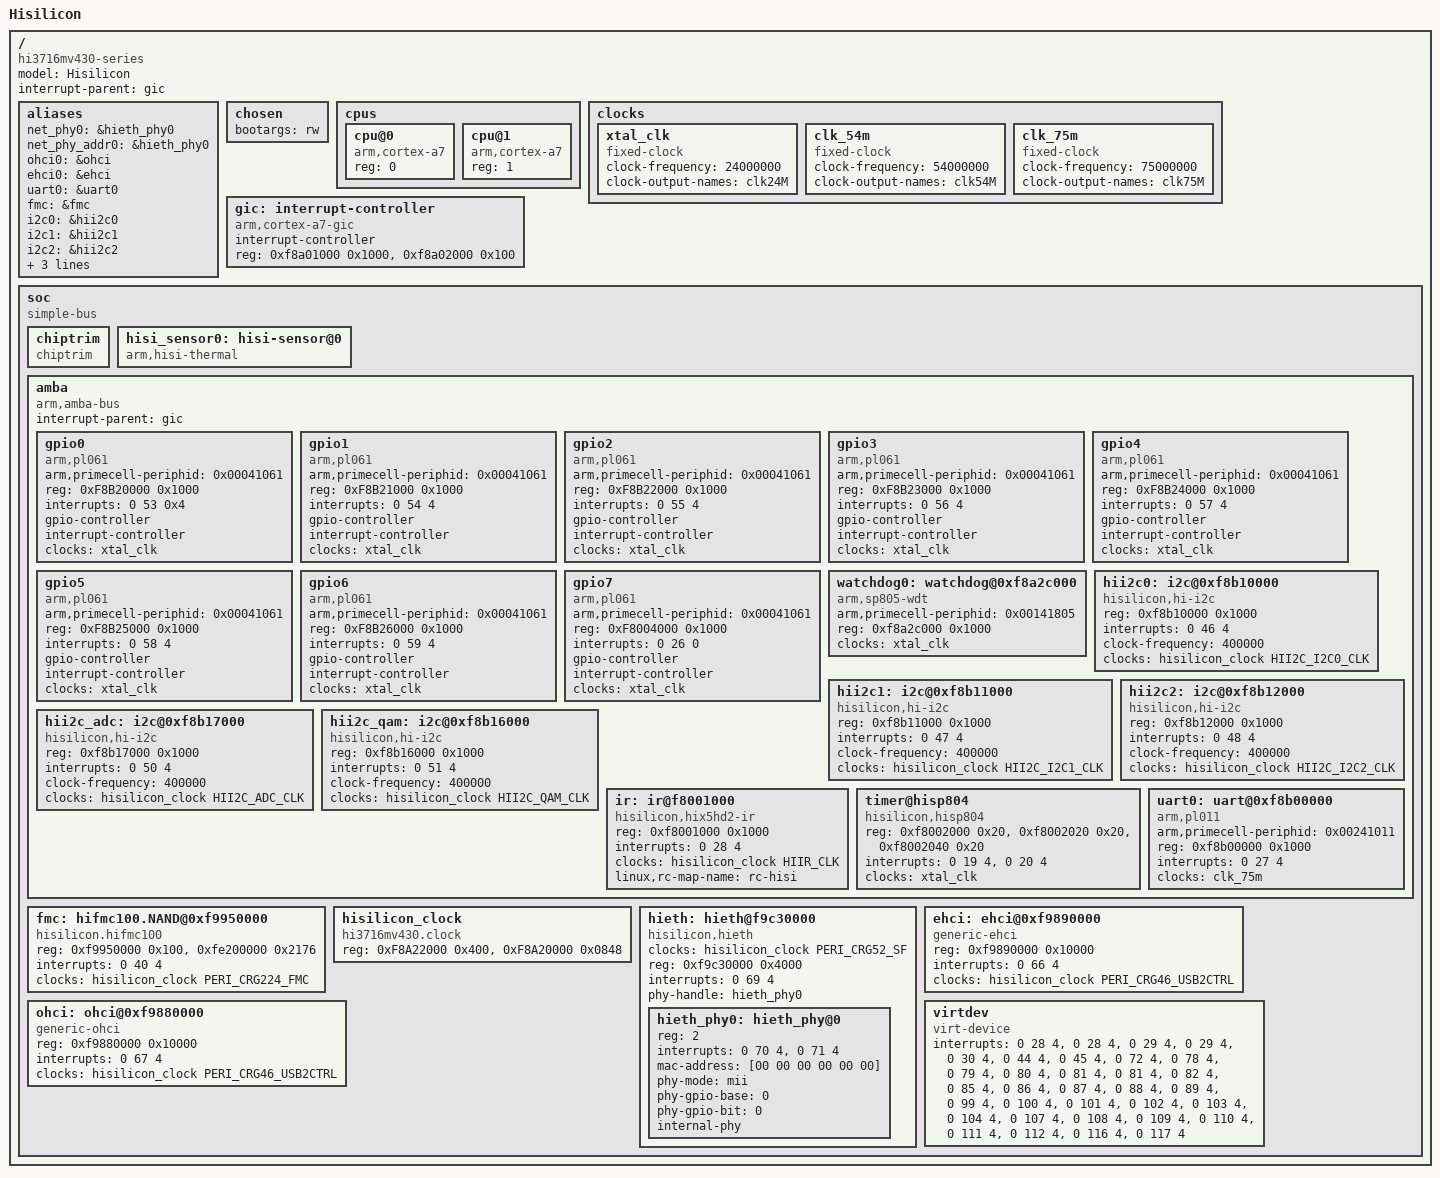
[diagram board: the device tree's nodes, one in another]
/dts-v1/;

#include <dt-bindings/clock/hi3716mv430-clock.h>

/ {
	model = "Hisilicon";
	compatible = "hi3716mv430-series";
	#address-cells = <1>;
	#size-cells = <1>;
	interrupt-parent = <&gic>;

	aliases {
		net_phy0 = &hieth_phy0;
		net_phy_addr0 = &hieth_phy0;
		ohci0= &ohci;
		ehci0= &ehci;
		uart0= &uart0;
		fmc  = &fmc;
		i2c0=&hii2c0;
		i2c1=&hii2c1;
		i2c2=&hii2c2;
		i2c3=&hii2c_qam;
		i2c4=&hii2c_adc;
		chiptrim=&chiptrim;
	};

	chosen {
		bootargs = "rw";
	};

	cpus {
		#address-cells = <1>;
		#size-cells = <0>;

		cpu@0 {
			device_type = "cpu";
			compatible = "arm,cortex-a7";
			reg = <0>;
		};

		cpu@1 {
			device_type = "cpu";
			compatible = "arm,cortex-a7";
			reg = <1>;
		};
	};

	clocks {
		xtal_clk: xtal_clk {
			compatible = "fixed-clock";
			#clock-cells = <0>;
			clock-frequency = <24000000>;
			clock-output-names = "clk24M";
		};

		clk_54m: clk_54m{
			compatible = "fixed-clock";
			#clock-cells = <0>;
			clock-frequency = <54000000>;
			clock-output-names = "clk54M";
		};

		clk_75m: clk_75m{
			compatible = "fixed-clock";
			#clock-cells = <0>;
			clock-frequency = <75000000>;
			clock-output-names = "clk75M";
		};
	};

	gic: interrupt-controller {
		compatible = "arm,cortex-a7-gic";
		#interrupt-cells = <3>;
		#address-cells = <0>;
		interrupt-controller;
		reg = <0xf8a01000 0x1000>,
		      <0xf8a02000 0x100>;
	};
	soc {
		#address-cells = <1>;
		#size-cells = <1>;
		compatible = "simple-bus";
		device_type = "soc";
		ranges = <0x0 0x0 0xffffffff>;

		chiptrim: chiptrim {
			compatible = "chiptrim";
		};

		hisi_sensor0: hisi-sensor@0 {
			compatible = "arm,hisi-thermal";
			#thermal-sensor-cells = <1>;
		};

		amba {
			compatible = "arm,amba-bus";
			#address-cells = <1>;
			#size-cells = <1>;
			interrupt-parent = <&gic>;
			ranges;

			gpio0: gpio0 {
				compatible = "arm,pl061", "arm,primecell";
				arm,primecell-periphid = <0x00041061>;
				reg = <0xF8B20000 0x1000>;
				interrupts = <0 53 0x4>;
				gpio-controller;
				#gpio-cells = <2>;
				interrupt-controller;
				#interrupt-cells = <2>;
				clocks = <&xtal_clk>;
				clock-names = "apb_pclk";
			};

			gpio1: gpio1 {
				compatible = "arm,pl061", "arm,primecell";
				arm,primecell-periphid = <0x00041061>;
				reg = <0xF8B21000 0x1000>;
				interrupts = <0 54 4>;
				gpio-controller;
				#gpio-cells = <2>;
				interrupt-controller;
				#interrupt-cells = <2>;
				clocks = <&xtal_clk>;
				clock-names = "apb_pclk";
			};

			gpio2: gpio2 {
				compatible = "arm,pl061", "arm,primecell";
				arm,primecell-periphid = <0x00041061>;
				reg = <0xF8B22000 0x1000>;
				interrupts = <0 55 4>;
				gpio-controller;
				#gpio-cells = <2>;
				interrupt-controller;
				#interrupt-cells = <2>;
				clocks = <&xtal_clk>;
				clock-names = "apb_pclk";
			};

			gpio3: gpio3 {
				compatible = "arm,pl061", "arm,primecell";
				arm,primecell-periphid = <0x00041061>;
				reg = <0xF8B23000 0x1000>;
				interrupts = <0 56 4>;
				gpio-controller;
				#gpio-cells = <2>;
				interrupt-controller;
				#interrupt-cells = <2>;
				clocks = <&xtal_clk>;
				clock-names = "apb_pclk";
			};

			gpio4: gpio4 {
				compatible = "arm,pl061", "arm,primecell";
				arm,primecell-periphid = <0x00041061>;
				reg = <0xF8B24000 0x1000>;
				interrupts = <0 57 4>;
				gpio-controller;
				#gpio-cells = <2>;
				interrupt-controller;
				#interrupt-cells = <2>;
				clocks = <&xtal_clk>;
				clock-names = "apb_pclk";
			};

			gpio5: gpio5 {
				compatible = "arm,pl061", "arm,primecell";
				arm,primecell-periphid = <0x00041061>;
				reg = <0xF8B25000 0x1000>;
				interrupts = <0 58 4>;
				gpio-controller;
				#gpio-cells = <2>;
				interrupt-controller;
				#interrupt-cells = <2>;
				clocks = <&xtal_clk>;
				clock-names = "apb_pclk";
			};

			gpio6: gpio6 {
				compatible = "arm,pl061", "arm,primecell";
				arm,primecell-periphid = <0x00041061>;
				reg = <0xF8B26000 0x1000>;
				interrupts = <0 59 4>;
				gpio-controller;
				#gpio-cells = <2>;
				interrupt-controller;
				#interrupt-cells = <2>;
				clocks = <&xtal_clk>;
				clock-names = "apb_pclk";
			};

			gpio7: gpio7 {
				compatible = "arm,pl061", "arm,primecell";
				arm,primecell-periphid = <0x00041061>;
				reg = <0xF8004000 0x1000>;
				interrupts = <0 26 0>;
				gpio-controller;
				#gpio-cells = <2>;
				interrupt-controller;
				#interrupt-cells = <2>;
				clocks = <&xtal_clk>;
				clock-names = "apb_pclk";
			};

			watchdog0: watchdog@0xf8a2c000 {
				compatible = "arm,sp805-wdt", "arm,primecell";
				arm,primecell-periphid = <0x00141805>;
				reg = <0xf8a2c000 0x1000>;
				clocks = <&xtal_clk>;
				clock-names = "apb_pclk";
			};

			hii2c0:i2c@0xf8b10000 {
				compatible = "hisilicon,hi-i2c";
				reg = <0xf8b10000 0x1000>;
				interrupts = <0 46 4>;
				clock-frequency = <400000>;
				clocks = <&hisilicon_clock HII2C_I2C0_CLK>;
				clock-names = "apb_pclk";
				#address-cells = <1>;
				#size-cells = <0>;
				status = "okay";
			};

			hii2c1:i2c@0xf8b11000 {
				compatible = "hisilicon,hi-i2c";
				reg = <0xf8b11000 0x1000>;
				interrupts = <0 47 4>;
				clock-frequency = <400000>;
				clocks = <&hisilicon_clock HII2C_I2C1_CLK>;
				clock-names = "apb_pclk";
				#address-cells = <1>;
				#size-cells = <0>;
				status = "okay";
			};

			hii2c2:i2c@0xf8b12000 {
				compatible = "hisilicon,hi-i2c";
				reg = <0xf8b12000 0x1000>;
				interrupts = <0 48 4>;
				clock-frequency = <400000>;
				clocks = <&hisilicon_clock HII2C_I2C2_CLK>;
				clock-names = "apb_pclk";
				#address-cells = <1>;
				#size-cells = <0>;
				status = "okay";
			};

			hii2c_adc:i2c@0xf8b17000 {
				compatible = "hisilicon,hi-i2c";
				reg = <0xf8b17000 0x1000>;
				interrupts = <0 50 4>;
				clock-frequency = <400000>;
				clocks = <&hisilicon_clock HII2C_ADC_CLK>;
				clock-names = "apb_pclk";
				#address-cells = <1>;
				#size-cells = <0>;
				status = "okay";
			};

			hii2c_qam:i2c@0xf8b16000 {
				compatible = "hisilicon,hi-i2c";
				reg = <0xf8b16000 0x1000>;
				interrupts = <0 51 4>;
				clock-frequency = <400000>;
				clocks = <&hisilicon_clock HII2C_QAM_CLK>;
				clock-names = "apb_pclk";
				#address-cells = <1>;
				#size-cells = <0>;
				status = "okay";
			};

			ir: ir@f8001000 {
				compatible = "hisilicon,hix5hd2-ir";
				reg = <0xf8001000 0x1000>;
				interrupts = <0 28 4>;
				clocks = <&hisilicon_clock HIIR_CLK>;
				linux,rc-map-name = "rc-hisi";
			};

			timer@hisp804 {
				compatible = "hisilicon,hisp804";
				reg = <0xf8002000 0x20>, /* clocksource */
					<0xf8002020 0x20>, /* local timer for each cpu */
					<0xf8002040 0x20>; /* local timer for each cpu */					

				interrupts = <0 19 4>, /* irq of local timer */
					<0 20 4>;
				clocks = <&xtal_clk>;
				clock-names = "apb_pclk";
			};

			uart0: uart@0xf8b00000 {
				compatible = "arm,pl011", "arm,primecell";
				arm,primecell-periphid = <0x00241011>;
				reg = <0xf8b00000 0x1000>;
				interrupts = <0 27 4>;
				clocks = <&clk_75m>;
				clock-names = "apb_pclk";
				status = "okay";
			};
		};

		fmc:hifmc100.NAND@0xf9950000 {
			compatible = "hisilicon.hifmc100";
			reg = <0xf9950000 0x100>, <0xfe200000 0x2176>;
			interrupts = <0 40 4>;

			clocks = <&hisilicon_clock PERI_CRG224_FMC>;
			clock-names = "clk";
			status = "okay";
		};

		hisilicon_clock: hisilicon_clock {
			compatible = "hi3716mv430.clock","hisilicon,clock-reset";
			reg = <0xF8A22000 0x400>, <0xF8A20000 0x0848>;
			#clock-cells = <1>;
			#reset-cells = <2>;
		};

		hieth: hieth@f9c30000 {
			compatible = "hisilicon,hieth";
			clocks = <&hisilicon_clock PERI_CRG52_SF>;
			clock-names = "clk";
			reg = <0xf9c30000 0x4000>;
			interrupts = <0 69 4>;
			phy-handle = <&hieth_phy0>;
			#address-cells = <1>;
			#size-cells = <0>;
			status = "okay";

			hieth_phy0: hieth_phy@0 {
				reg = <2>;
				interrupts = <0 70 4>, <0 71 4>;
				mac-address = [00 00 00 00 00 00];
				phy-mode = "mii";
				phy-gpio-base = <0>;
				phy-gpio-bit = <0>;
				internal-phy;
			};
		};


		ehci:ehci@0xf9890000 {
			compatible = "generic-ehci";
			reg = <0xf9890000 0x10000>;
			interrupts = <0 66 4>;

			clocks = <&hisilicon_clock PERI_CRG46_USB2CTRL>;
			clock-names = "clk";
			status = "okay";
		};

		ohci:ohci@0xf9880000 {
			compatible = "generic-ohci";
			reg = <0xf9880000 0x10000>;
			interrupts = <0 67 4>;

			clocks = <&hisilicon_clock PERI_CRG46_USB2CTRL>;
			clock-names = "clk";
			status = "okay";
		};

		virtdev {
			compatible = "virt-device";
			interrupts = <0 28 4>,  /* "ir_std"        */
						 <0 28 4>,  /* "ir_s2"         */
						 <0 29 4>,  /* "keyled_ct1642" */
						 <0 29 4>,  /* "keyled_std"    */
						 <0 30 4>,  /* "hdmi_cec"      */
						 <0 44 4>,  /* "sci0"          */
						 <0 45 4>,  /* "sci1"          */
						 <0 72 4>,  /* "gsf0"          */
						 <0 78 4>,  /* "hdmi"          */
						 <0 79 4>,  /* "aiao"          */
						 <0 80 4>,  /* "vdp"           */
						 <0 81 4>,  /* "tde"           */
						 <0 81 4>,  /* "gfx2d"         */
						 <0 82 4>,  /* "intdpp"        */
						 <0 85 4>,  /* "jpeg"          */
						 <0 86 4>,  /* "vdec_vdh"      */
						 <0 87 4>,  /* "vdec_vdh_safe" */
						 <0 88 4>,  /* "vdec_scd"      */
						 <0 89 4>,  /* "vdec_scd_safe" */
						 <0 99 4>,  /* "dmx"           */
						 <0 100 4>, /* "cipher"        */
						 <0 101 4>, /* "multicipher"   */
						 <0 102 4>, /* "hkl_acpu"      */
						 <0 103 4>, /* "hkl_tzcpu"     */
						 <0 104 4>, /* "sha3"          */
						 <0 107 4>, /* "rsa"           */
						 <0 108 4>, /* "rsa_err"       */
						 <0 109 4>, /* "plcipher"      */
						 <0 110 4>, /* "plcipher_safe" */
						 <0 111 4>, /* "scpu_mailbox   */
						 <0 112 4>, /* "tcpu_mailbox   */
						 <0 116 4>, /* "akl_ree"       */
						 <0 117 4>; /* "akl_tee"       */
			interrupt-names = /* 28  */ "ir_std",
							  /* 28  */ "ir_s2",
							  /* 29  */ "keyled_ct1642",
							  /* 29  */ "keyled_std",
							  /* 30  */ "hdmi_cec",
							  /* 44  */ "sci0",
							  /* 45  */ "sci1",
							  /* 72  */ "gsf0",
							  /* 78  */ "hdmi",
							  /* 79  */ "aiao",
							  /* 80  */ "vdp",
							  /* 81  */ "tde",
							  /* 81  */ "gfx2d",
							  /* 82  */ "intdpp",
							  /* 85  */ "jpeg",
							  /* 86  */ "vdec_vdh",
							  /* 87  */ "vdec_vdh_safe",
							  /* 88  */ "vdec_scd",
							  /* 89  */ "vdec_scd_safe",
							  /* 99  */ "dmx",
						 	  /* 100 */ "cipher",
						 	  /* 101 */ "multicipher",
						 	  /* 102 */ "hkl_acpu",
						 	  /* 103 */ "hkl_tzcpu",
						 	  /* 104 */ "sha3",
						 	  /* 107 */ "rsa",
						 	  /* 108 */ "rsa_err",
							  /* 109 */ "plcipher",
							  /* 110 */ "plcipher_safe",
							  /* 111 */ "scpu_mailbox",
							  /* 112 */ "tcpu_mailbox",
							  /* 116 */ "akl_ree",
							  /* 117 */ "akl_tee";
		};
	};
};
